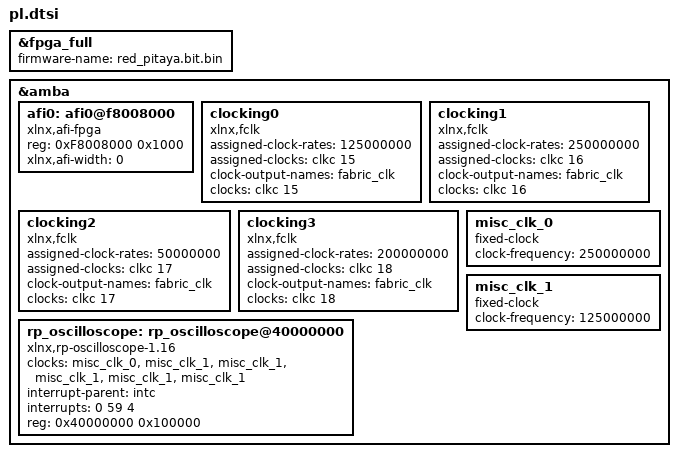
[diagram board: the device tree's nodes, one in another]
/*
 * CAUTION: This file is automatically generated by Xilinx.
 * Version:  
 * Today is: Mon Aug 21 09:28:55 2023
 */


/dts-v1/;
/plugin/;
/ {
	fragment@0 {
		target = <&fpga_full>;
		overlay0: __overlay__ {
			#address-cells = <2>;
			#size-cells = <2>;
			firmware-name = "red_pitaya.bit.bin";
		};
	};
	fragment@1 {
		target = <&amba>;
		overlay1: __overlay__ {
			afi0: afi0@f8008000 {
				#address-cells = <1>;
				#size-cells = <0>;
				compatible = "xlnx,afi-fpga";
				reg = <0xF8008000 0x1000>;
				xlnx,afi-width = <0>;
			};
			clocking0: clocking0 {
				#clock-cells = <0>;
				assigned-clock-rates = <125000000>;
				assigned-clocks = <&clkc 15>;
				clock-output-names = "fabric_clk";
				clocks = <&clkc 15>;
				compatible = "xlnx,fclk";
			};
			clocking1: clocking1 {
				#clock-cells = <0>;
				assigned-clock-rates = <250000000>;
				assigned-clocks = <&clkc 16>;
				clock-output-names = "fabric_clk";
				clocks = <&clkc 16>;
				compatible = "xlnx,fclk";
			};
			clocking2: clocking2 {
				#clock-cells = <0>;
				assigned-clock-rates = <50000000>;
				assigned-clocks = <&clkc 17>;
				clock-output-names = "fabric_clk";
				clocks = <&clkc 17>;
				compatible = "xlnx,fclk";
			};
			clocking3: clocking3 {
				#clock-cells = <0>;
				assigned-clock-rates = <200000000>;
				assigned-clocks = <&clkc 18>;
				clock-output-names = "fabric_clk";
				clocks = <&clkc 18>;
				compatible = "xlnx,fclk";
			};
		};
	};
	fragment@2 {
		target = <&amba>;
		overlay2: __overlay__ {
			#address-cells = <1>;
			#size-cells = <1>;
			rp_oscilloscope: rp_oscilloscope@40000000 {
				clock-names = "clk", "s_axi_reg_aclk", "m_axi_osc1_aclk", "m_axi_osc2_aclk", "m_axi_osc3_aclk", "m_axi_osc4_aclk";
				clocks = <&misc_clk_0>, <&misc_clk_1>, <&misc_clk_1>, <&misc_clk_1>, <&misc_clk_1>, <&misc_clk_1>;
				compatible = "xlnx,rp-oscilloscope-1.16";
				interrupt-names = "intr";
				interrupt-parent = <&intc>;
				interrupts = <0 59 4>;
				reg = <0x40000000 0x100000>;
			};
			misc_clk_0: misc_clk_0 {
				#clock-cells = <0>;
				clock-frequency = <250000000>;
				compatible = "fixed-clock";
			};
			misc_clk_1: misc_clk_1 {
				#clock-cells = <0>;
				clock-frequency = <125000000>;
				compatible = "fixed-clock";
			};
		};
	};
};
